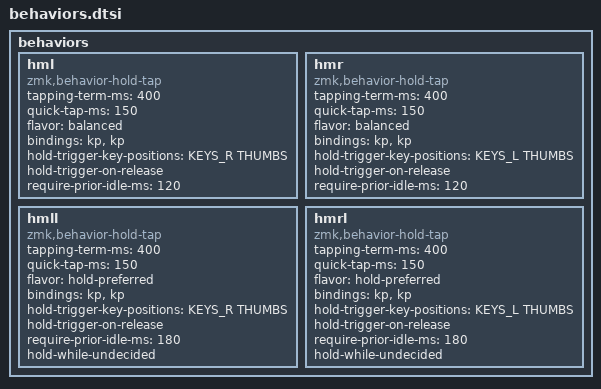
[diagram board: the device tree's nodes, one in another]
behaviors {
    hml: hml {
        compatible = "zmk,behavior-hold-tap";
        tapping-term-ms = <400>;
        quick-tap-ms = <150>;
        flavor = "balanced";
        #binding-cells = <2>;
        bindings = <&kp>, <&kp>;
        hold-trigger-key-positions = <KEYS_R THUMBS>;
        hold-trigger-on-release;
        require-prior-idle-ms = <120>;
    };
    hmr: hmr {
        compatible = "zmk,behavior-hold-tap";
        tapping-term-ms = <400>;
        quick-tap-ms = <150>;
        flavor = "balanced";
        #binding-cells = <2>;
        bindings = <&kp>, <&kp>;
        hold-trigger-key-positions = <KEYS_L THUMBS>;
        hold-trigger-on-release;
        require-prior-idle-ms = <120>;
    };
    hmll: hmll {
        compatible = "zmk,behavior-hold-tap";
        tapping-term-ms = <400>;
        quick-tap-ms = <150>;
        flavor = "hold-preferred";
        #binding-cells = <2>;
        bindings = <&kp>, <&kp>;
        hold-trigger-key-positions = <KEYS_R THUMBS>;
        hold-trigger-on-release;
        require-prior-idle-ms = <180>;
        hold-while-undecided;
    };
    hmrl: hmrl {
        compatible = "zmk,behavior-hold-tap";
        tapping-term-ms = <400>;
        quick-tap-ms = <150>;
        flavor = "hold-preferred";
        #binding-cells = <2>;
        bindings = <&kp>, <&kp>;
        hold-trigger-key-positions = <KEYS_L THUMBS>;
        hold-trigger-on-release;
        require-prior-idle-ms = <180>;
        hold-while-undecided;
    };
};

